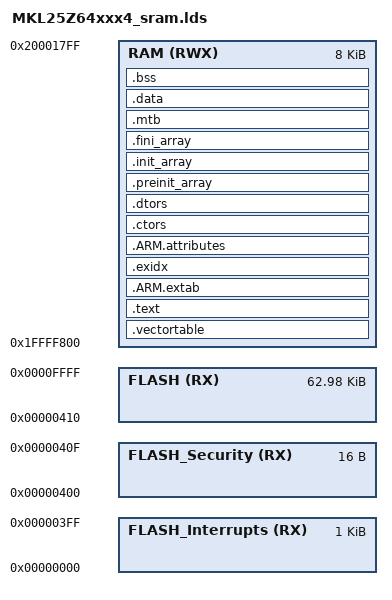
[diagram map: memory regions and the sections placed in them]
/* Generated by LinkerScriptGenerator [http://visualgdb.com/tools/LinkerScriptGenerator]
 * Target: MKL25Z64xxx4
 * The file is provided under the BSD license.
 */

ENTRY(Reset_Handler)

MEMORY
{
	FLASH (RX)            : ORIGIN = 0x00000410, LENGTH = 0xfbf0
	FLASH_Interrupts (RX) : ORIGIN = 0x00000000, LENGTH = 1K
	FLASH_Security (RX)   : ORIGIN = 0x00000400, LENGTH = 0x10
	RAM (RWX)             : ORIGIN = 0x1ffff800, LENGTH = 8K
}

_estack = 0x20001800;

SECTIONS
{
	.vectortable :
	{
		. = ALIGN(4);
		KEEP(*(.vectortable))
		. = ALIGN(4);
	} > RAM

	.text :
	{
		. = ALIGN(4);
		_stext = .;

		*(.text)
		*(.text*)
		*(.rodata)
		*(.rodata*)
		*(.glue_7)
		*(.glue_7t)
		*(.eh_frame)
		KEEP(*(.init))
		KEEP(*(.fini))
		. = ALIGN(4);
		_etext = .;

	} > RAM

	.ARM.extab :
	{
		. = ALIGN(4);
		*(.ARM.extab)
		*(.gnu.linkonce.armextab.*)
		. = ALIGN(4);
	} > RAM

	.exidx :
	{
		. = ALIGN(4);
		PROVIDE(__exidx_start = .);
		*(.ARM.exidx*)
		. = ALIGN(4);
		PROVIDE(__exidx_end = .);
	} > RAM

	.ARM.attributes :
	{
		*(.ARM.attributes)
	} > RAM

	.ctors :
	{
		. = ALIGN(4);
		__CTOR_LIST__ = .;
		KEEP(*crtbegin.o(.ctors))
		KEEP(*(EXCLUDE_FILE (*crtend.o ) .ctors))
		KEEP(*(SORT(.ctors.*)))
		KEEP(*(.ctors*))
		. = ALIGN(4);
		__CTOR_END__ = .;
	} > RAM

	.dtors :
	{
		. = ALIGN(4);
		__DTOR_LIST__ = .;
		KEEP(*crtbegin.o(.dtors))
		KEEP(*(EXCLUDE_FILE (*crtend.o ) .dtors))
		KEEP(*(SORT(.dtors.*)))
		KEEP(*(.dtors*))
		. = ALIGN(4);
		__DTOR_END__ = .;
	} > RAM

	.preinit_array :
	{
		PROVIDE(__preinit_array_start = .);
		KEEP(*(.preinit_array*))
		PROVIDE(__preinit_array_end = .);
	} > RAM

	.init_array :
	{
		PROVIDE(__init_array_start = .);
		KEEP(*(SORT(.init_array.*)))
		KEEP(*(.init_array*))
		PROVIDE(__init_array_end = .);
	} > RAM

	.fini_array :
	{
		PROVIDE(__fini_array_start = .);
		KEEP(*(.fini_array*))
		KEEP(*(SORT(.fini_array.*)))
		PROVIDE(__fini_array_end = .);
	} > RAM

	.mtb :
	{
		. = ALIGN(8);
		_mtb_start = .;
		KEEP(*(.mtb_buf))
		. = ALIGN(8);
		_mtb_end = .;
	} > RAM

	.data :
	{
		. = ALIGN(4);
		_sidata = .;

		_sdata = _sidata;

		PROVIDE(__data_start__ = _sdata);
		*(.data)
		*(.data*)
		. = ALIGN(4);
		_edata = .;

		PROVIDE(__data_end__ = _edata);
	} > RAM

	.bss :
	{
		. = ALIGN(4);
		_sbss = .;

		PROVIDE(__bss_start__ = _sbss);
		*(.bss)
		*(.bss*)
		*(COMMON)
		. = ALIGN(4);
		_ebss = .;

		PROVIDE(__bss_end__ = _ebss);
	} > RAM

	PROVIDE(end = .);

}

